# WS53 register map
File version: 0.1.0-experimental
Registers are 32-bit, read-write, no defined reset value unless marked. A register's access mark holds for its fields unless they carry their own. Offsets are from the block's base; [hi:lo] are bit positions; {n}, {i} and the like mark numbered series.

## KM
Base 0x52022000
{0x1000+4i} DATA_IN[{i}] (i=0..3) wo — Clear-key staging write: source writes four little-endian words, zero-pads and clears them afterwards. Readback is not evidenced; zero writes after timeout are not proof of route completion or slot erasure
  [31:0] VALUE
0x1010 KEY_ADDRESS — Shared destination selector; MCIPHER slot times2 with parity in bit0, HMAC unshifted slot. Field width is not the available slot count; SDK allocation limits are8/2 respectively
  [9:0] ADDRESS
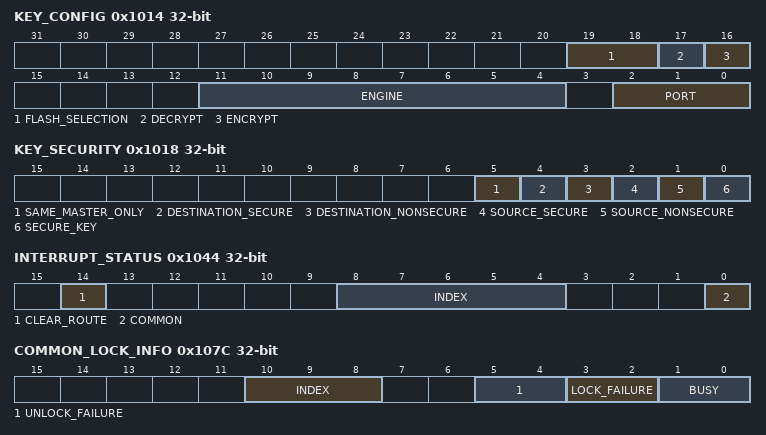
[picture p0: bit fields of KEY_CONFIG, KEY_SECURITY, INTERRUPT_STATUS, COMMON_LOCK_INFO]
0x1014 KEY_CONFIG — Volatile working-key policy/configuration. SDK ports1 MCIPHER/HMAC,7 Flash; engine codes0x20 AES,0x50 SM4,0xa0/0xa1/0xa2 HMAC. Layout is not chip algorithm availability or authorization to affect live Flash decryption
  [19:18] FLASH_SELECTION, [17] DECRYPT, [16] ENCRYPT, [11:4] ENGINE, [2:0] PORT
0x1018 KEY_SECURITY — Volatile working-key buffer/security permissions from SDK; not eFuse or permanent security configuration. Requires explicit ownership and correct CPU/security domain
  [5] SAME_MASTER_ONLY, [4] DESTINATION_SECURE, [3] DESTINATION_NONSECURE, [2] SOURCE_SECURE, [1] SOURCE_NONSECURE, [0] SECURE_KEY
0x1038 LOADER_ERROR ro — Opaque KL error read; SDK treats any nonzero as failure. No clear semantics evidenced
  [31:0] VALUE
0x103C CONTROLLER_ERROR ro — Opaque key-controller error read; no error-clear semantics evidenced
  [31:0] VALUE
0x1044 INTERRUPT_STATUS ro — Low32-bit raw interrupt read used by source. Header union has an overlong reserved tail; register access remains32-bit. Interrupt number/delivery and ACK behavior not silicon-qualified
  [14] CLEAR_ROUTE, [8:4] INDEX, [0] COMMON
0x1044 INTERRUPT_ACK wo (alternate view of INTERRUPT_STATUS) — Source writes entire prior raw value OR bit14; not a proven isolated W1C and may acknowledge other pending causes. Command deliberately has no modify/read/reset API
  [31:0] VALUE
0x1074 COMMON_LOCK wo — Source common/root-route lock request writes1; this does not establish exclusion of the clear-key loader
  [31:0] VALUE
0x1078 COMMON_UNLOCK wo — Source common/root-route unlock request writes1; successful request alone is not a reread of owner
  [31:0] VALUE
0x107C COMMON_LOCK_INFO ro
  [10:8] INDEX, [5:4] UNLOCK_FAILURE, [3:2] LOCK_FAILURE, [1:0] BUSY
0x1080 COMMON_OWNER ro — Common-route owner; source expects0xaa for ACPU. Clear-route exclusion is not established
  [7:0] OWNER
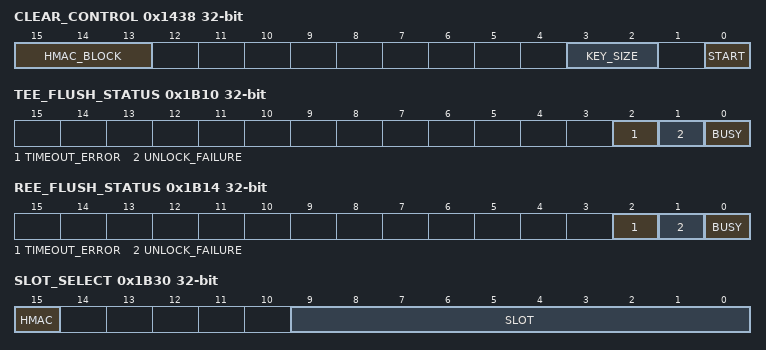
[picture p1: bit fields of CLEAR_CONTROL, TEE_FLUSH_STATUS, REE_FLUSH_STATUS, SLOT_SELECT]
0x1438 CLEAR_CONTROL ro — Clear-route read view; source polls START until zero and then reads both error words. Busy/idle does not certify slot erasure, DMA drain or cross-core handback
  [15:13] HMAC_BLOCK, [3:2] KEY_SIZE, [0] START
0x1438 CLEAR_SUBMIT wo (alternate view of CLEAR_CONTROL) — Clear-route command: SYMC preserves readback and writes START1/key-size1,2,3; HMAC sends fresh START1/block0..7. No abort or forced-clear semantics
  [31:0] VALUE
0x1B00 TEE_SLOT_READ ro
  [31:0] VALUE
0x1B00 TEE_SLOT_COMMAND wo (alternate view of TEE_SLOT_READ) — TEE slot lock/flush command readback preserved by SDK. low10 slot, bit15 HMAC, bit20 lock1/unlock0; slot count and completion require independent validation
  [31:0] VALUE
0x1B04 REE_SLOT_READ ro
  [31:0] VALUE
0x1B04 REE_SLOT_COMMAND wo (alternate view of REE_SLOT_READ) — ACPU/REE slot lock/flush command. Separate write view prevents read-modify-write convenience on a command; construct from validated selection and explicit prior readback
  [31:0] VALUE
0x1B10 TEE_FLUSH_STATUS ro
  [2] TIMEOUT_ERROR, [1] UNLOCK_FAILURE, [0] BUSY
0x1B14 REE_FLUSH_STATUS ro
  [2] TIMEOUT_ERROR, [1] UNLOCK_FAILURE, [0] BUSY
0x1B30 SLOT_SELECT — Global selector for SLOT_OWNER, shared with all CPU/security clients. Selector write/read must remain within an exclusive KM transaction; field width is not capacity
  [15] HMAC, [9:0] SLOT
0x1B34 SLOT_OWNER ro — Owner of globally selected slot; original enum/call path use1 REE,2 TEE. Contradictory unused header bit-pattern macros are not adopted. No read-clear semantics evidenced
  [2:0] OWNER
